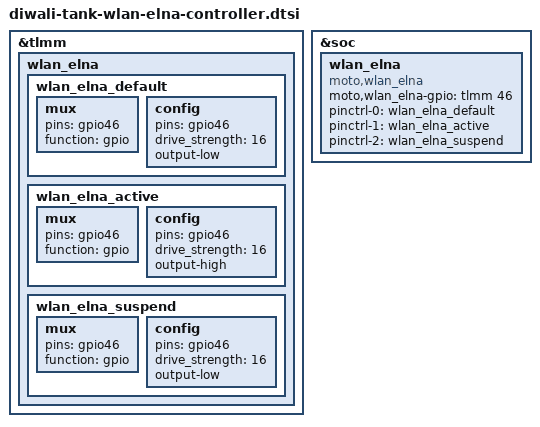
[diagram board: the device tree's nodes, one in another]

&tlmm {
	wlan_elna{
        wlan_elna_default: wlan_elna_default {
            mux {
                    pins = "gpio46";
                    function = "gpio";
            };
            config {
                    pins = "gpio46";
                    drive_strength = <16>;
                    output-low;
            };
        };

        wlan_elna_active: wlan_elna_active {
            mux {
                    pins = "gpio46";
                    function = "gpio";
            };
            config {
                    pins = "gpio46";
                    drive_strength = <16>;
                    output-high;
            };
        };

        wlan_elna_suspend: wlan_elna_suspend {
            mux {
                    pins = "gpio46";
                    function = "gpio";
            };
            config {
                    pins = "gpio46";
                    drive_strength = <16>;
                    output-low;
            };
        };
	};
};

&soc {
	wlan_elna: wlan_elna{
		status = "ok";
		compatible = "moto,wlan_elna";
		moto,wlan_elna-gpio = <&tlmm 46 0>;
		pinctrl-names = "default", "elna_active", "elna_suspend";
		pinctrl-0 = <&wlan_elna_default>;
		pinctrl-1 = <&wlan_elna_active>;
		pinctrl-2 = <&wlan_elna_suspend>;
	};
};
